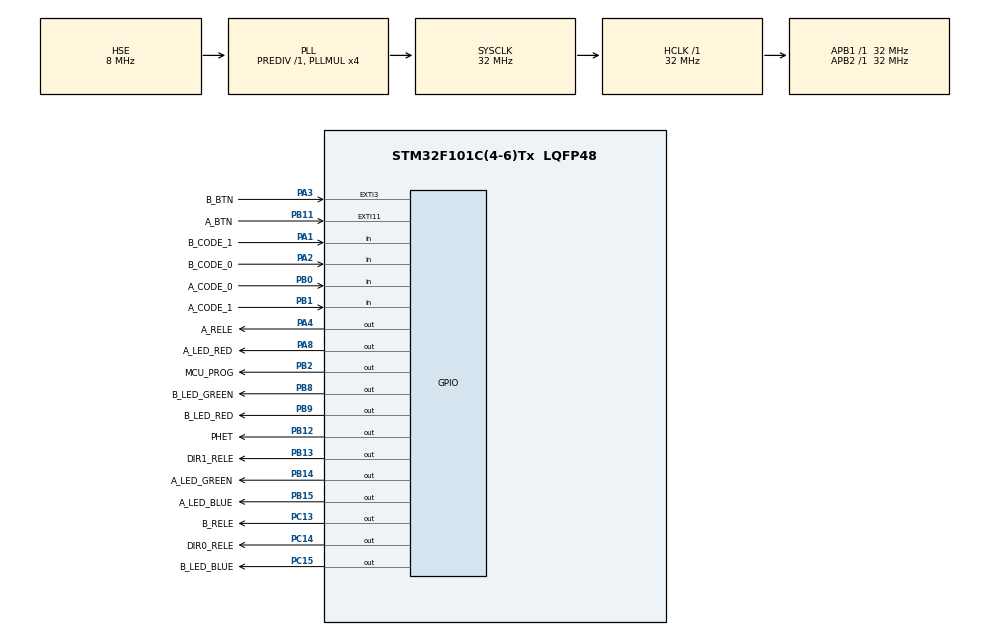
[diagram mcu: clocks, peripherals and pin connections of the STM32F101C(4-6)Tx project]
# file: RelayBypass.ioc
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Mcu.Family=STM32F1
PB14.GPIO_Label=A_LED_GREEN
NVIC.EXTI3_IRQn=true\:1\:0\:true\:false\:true\:true\:true
PB0.GPIO_Label=A_CODE_0
PB13.GPIO_Label=DIR1_RELE
PB11.Signal=GPXTI11
PB13.Signal=GPIO_Output
PB15.Signal=GPIO_Output
PC15-OSC32_OUT.GPIO_Label=B_LED_BLUE
RCC.SYSCLKSource=RCC_SYSCLKSOURCE_PLLCLK
ProjectManager.StackSize=0x400
PD1-OSC_OUT.Signal=RCC_OSC_OUT
RCC.HCLKFreq_Value=32000000
RCC.AHBFreq_Value=32000000
NVIC.EXTI15_10_IRQn=true\:1\:0\:true\:false\:true\:true\:true
PB2.Signal=GPIO_Output
PB12.GPIO_ModeDefaultOutputPP=GPIO_MODE_OUTPUT_PP
RCC.PLLMUL=RCC_PLL_MUL4
PB12.GPIO_Label=PHET
PA14.Mode=Serial_Wire
PB1.GPIO_Label=A_CODE_1
NVIC.TIM2_IRQn=true\:0\:0\:true\:false\:true\:true\:true
PA8.Signal=GPIO_Output
PB9.Signal=GPIO_Output
Mcu.Package=LQFP48
TIM2.Prescaler=32000
PB1.Signal=GPIO_Input
PA2.GPIO_Label=B_CODE_0
PB11.GPIO_ModeDefaultEXTI=GPIO_MODE_IT_FALLING
RCC.APB1TimFreq_Value=32000000
PC14-OSC32_IN.GPIO_Label=DIR0_RELE
PA4.GPIO_Label=A_RELE
PA3.Signal=GPXTI3
RCC.PLLSourceVirtual=RCC_PLLSOURCE_HSE
PD1-OSC_OUT.Mode=HSE-External-Oscillator
PB9.GPIO_Label=B_LED_RED
PB11.GPIO_Label=A_BTN
PC13-TAMPER-RTC.Signal=GPIO_Output
PD0-OSC_IN.Signal=RCC_OSC_IN
PC14-OSC32_IN.Signal=GPIO_Output
PA3.GPIO_ModeDefaultEXTI=GPIO_MODE_IT_FALLING
RCC.ADCPresc=RCC_ADCPCLK2_DIV4
PA13.Signal=SYS_JTMS-SWDIO
PB8.GPIO_Label=B_LED_GREEN
PA8.GPIO_Label=A_LED_RED
ProjectManager.TargetToolchain=STM32CubeIDE
PC15-OSC32_OUT.Signal=GPIO_Output
PA1.Signal=GPIO_Input
PD0-OSC_IN.Mode=HSE-External-Oscillator
PB14.Signal=GPIO_Output
board=custom
PC13-TAMPER-RTC.GPIO_Label=B_RELE
RCC.APB2Freq_Value=32000000
PB15.GPIO_Label=A_LED_BLUE
VP_TIM2_VS_ClockSourceINT.Mode=Internal
PA1.GPIO_Label=B_CODE_1
TIM2.Period=125
PA13.Mode=Serial_Wire
Mcu.Name=STM32F101C(4-6)Tx
PA2.Signal=GPIO_Input
PA4.Signal=GPIO_Output
RCC.SYSCLKFreq_VALUE=32000000
PA14.Signal=SYS_JTCK-SWCLK
PB2.GPIO_Label=MCU_PROG
ProjectManager.HeapSize=0x200
NVIC.PriorityGroup=NVIC_PRIORITYGROUP_4
TIM2.TIM_MasterSlaveMode=TIM_MASTERSLAVEMODE_DISABLE
PB8.Signal=GPIO_Output
TIM2.AutoReloadPreload=TIM_AUTORELOAD_PRELOAD_ENABLE
PB12.GPIO_PuPd=GPIO_NOPULL
RCC.APB1Freq_Value=32000000
PB0.Signal=GPIO_Input
PB12.Signal=GPIO_Output
PA3.GPIO_Label=B_BTN

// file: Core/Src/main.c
/* USER CODE BEGIN Header */
/**
  ******************************************************************************
  * @file           : main.c
  * @brief          : Main program body
  ******************************************************************************
  * @attention
  *
  * <h2><center>&copy; Copyright (c) 2021 STMicroelectronics.
  * All rights reserved.</center></h2>
  *
  * This software component is licensed by ST under BSD 3-Clause license,
  * the "License"; You may not use this file except in compliance with the
  * License. You may obtain a copy of the License at:
  *                        opensource.org/licenses/BSD-3-Clause
  *
  ******************************************************************************
  */
/* USER CODE END Header */
#include "main.h"
#include "tim.h"
#include "gpio.h"

/* USER CODE BEGIN Includes */
#include "../../Include/Executor.h"
/* USER CODE END Includes */

void SystemClock_Config(void);

int main(void)
{

  /* MCU Configuration--------------------------------------------------------*/

  /* Reset of all peripherals, Initializes the Flash interface and the Systick. */
  HAL_Init();

  /* Configure the system clock */
  SystemClock_Config();

  /* Initialize all configured peripherals */
  MX_GPIO_Init();
  MX_TIM2_Init();
  /* USER CODE BEGIN 2 */
  Status status = FAIL;

  Executor *pExecutor = Executor_Create();

  if(pExecutor == NULL)
  {
      Error_Handler();
  }

  /* USER CODE END 2 */

  /* Infinite loop */
  /* USER CODE BEGIN WHILE */
  while (1)
  {
    status = Executor_Handler(pExecutor);
    /* USER CODE END WHILE */

  }
}

void SystemClock_Config(void)
{
  RCC_OscInitTypeDef RCC_OscInitStruct = {0};
  RCC_ClkInitTypeDef RCC_ClkInitStruct = {0};

  /** Initializes the RCC Oscillators according to the specified parameters
  * in the RCC_OscInitTypeDef structure.
  */
  RCC_OscInitStruct.OscillatorType = RCC_OSCILLATORTYPE_HSE;
  RCC_OscInitStruct.HSEState = RCC_HSE_ON;
  RCC_OscInitStruct.HSEPredivValue = RCC_HSE_PREDIV_DIV1;
  RCC_OscInitStruct.HSIState = RCC_HSI_ON;
  RCC_OscInitStruct.PLL.PLLState = RCC_PLL_ON;
  RCC_OscInitStruct.PLL.PLLSource = RCC_PLLSOURCE_HSE;
  RCC_OscInitStruct.PLL.PLLMUL = RCC_PLL_MUL4;
  if (HAL_RCC_OscConfig(&RCC_OscInitStruct) != HAL_OK)
  {
    Error_Handler();
  }
  /** Initializes the CPU, AHB and APB buses clocks
  */
  RCC_ClkInitStruct.ClockType = RCC_CLOCKTYPE_HCLK|RCC_CLOCKTYPE_SYSCLK
                              |RCC_CLOCKTYPE_PCLK1|RCC_CLOCKTYPE_PCLK2;
  RCC_ClkInitStruct.SYSCLKSource = RCC_SYSCLKSOURCE_PLLCLK;
  RCC_ClkInitStruct.AHBCLKDivider = RCC_SYSCLK_DIV1;
  RCC_ClkInitStruct.APB1CLKDivider = RCC_HCLK_DIV1;
  RCC_ClkInitStruct.APB2CLKDivider = RCC_HCLK_DIV1;

  if (HAL_RCC_ClockConfig(&RCC_ClkInitStruct, FLASH_LATENCY_1) != HAL_OK)
  {
    Error_Handler();
  }
}

void Error_Handler(void)
{
  __disable_irq();
  while (1)
  {
  }
}

/************************ (C) COPYRIGHT STMicroelectronics *****END OF FILE****/
